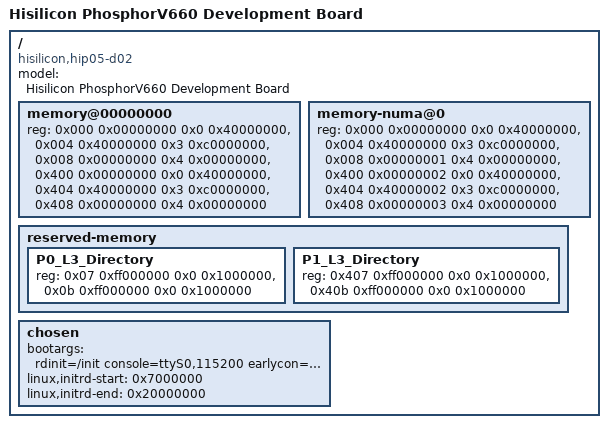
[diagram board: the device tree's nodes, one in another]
/**
 * dts file for Hisilicon PhosphorV660 EVB Board
 *
 * Copyright (C) 2014,2015 Hisilicon Ltd.
 *
 * This program is free software; you can redistribute it and/or modify
 * it under the terms of the GNU General Public License version 2 as
 * publishhed by the Free Software Foundation.
 *
 */

/dts-v1/;

/memreserve/ 0x00000000 0x00010000;
/include/ "hisi_hi1610_2p.dtsi"

/ {
	model = "Hisilicon PhosphorV660 Development Board";
	compatible = "hisilicon,hip05-d02", "hisilicon,hisi-pv660";

	memory@00000000 {
		device_type = "memory";
		reg = <0x000 0x00000000 0x0 0x40000000>,
		      <0x004 0x40000000 0x3 0xc0000000>,
		      <0x008 0x00000000 0x4 0x00000000>,
		      <0x400 0x00000000 0x0 0x40000000>,
		      <0x404 0x40000000 0x3 0xc0000000>,
		      <0x408 0x00000000 0x4 0x00000000>;
	};

	memory-numa@0 {
		reg = <0x000 0x00000000 0x0 0x40000000>,
		      <0x004 0x40000000 0x3 0xc0000000>,
		      <0x008 0x00000001 0x4 0x00000000>,
		      <0x400 0x00000002 0x0 0x40000000>,
		      <0x404 0x40000002 0x3 0xc0000000>,
		      <0x408 0x00000003 0x4 0x00000000>;
	};

	reserved-memory {
		#address-cells = <0x2>;
		#size-cells = <0x2>;
		ranges;

		P0_L3_Directory {
			status = "ok";
			reg = <0x07 0xff000000 0x0 0x1000000>,
			      <0x0b 0xff000000 0x0 0x1000000>;
		};

		P1_L3_Directory {
			status = "ok";
			reg = <0x407 0xff000000 0x0 0x1000000>,
			      <0x40b 0xff000000 0x0 0x1000000>;
		};
	};

	chosen {
		bootargs = "rdinit=/init console=ttyS0,115200 earlycon=uart8250,mmio32,0x60300000";
		linux,initrd-start = <0x7000000>;
		linux,initrd-end = <0x20000000>;
	};
};
